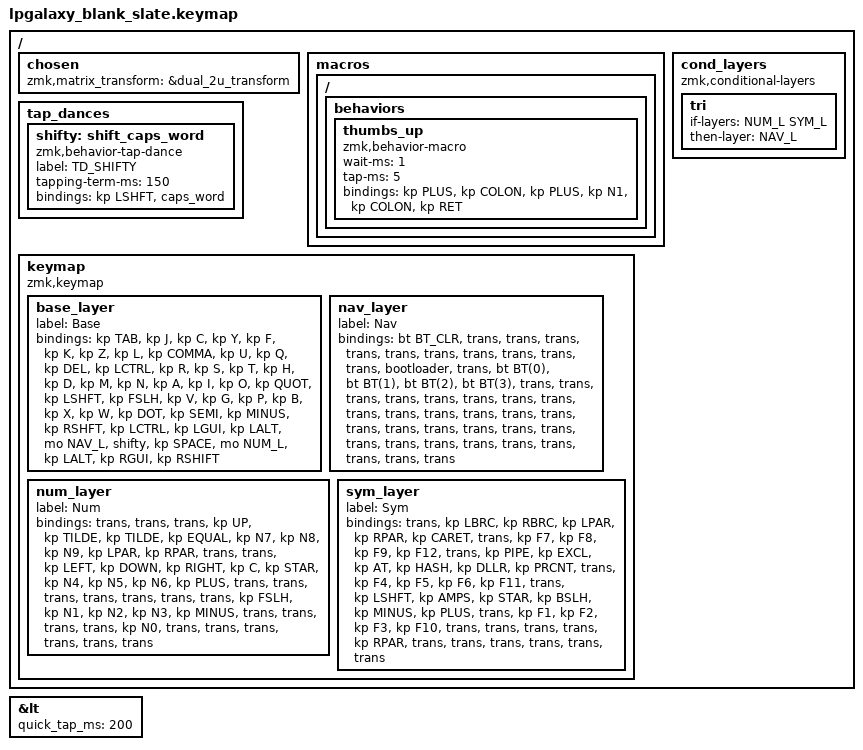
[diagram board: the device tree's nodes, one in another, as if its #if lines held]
/*
 * Copyright (c) 2022 Pete Johanson
 *
 * SPDX-License-Identifier: MIT
 */

#include <behaviors.dtsi>
#include <dt-bindings/zmk/keys.h>
#include <dt-bindings/zmk/bt.h>
#include <dt-bindings/zmk/outputs.h>

#define QWERTY_BASE 1

#define TBLE_ORTHO   1
// #define TBLE_MIT     1
// #define TBLE_DUAL_2U 1

#define NAV_L 1
#define NUM_L 2
#define SYM_L 3

// Using layer taps on thumbs, having quick tap as well helps w/ repeating space/backspace
&lt { quick_tap_ms = <200>; };

#define BT(n) BT_SEL n

/ {
    chosen {
       zmk,matrix_transform =
#ifdef TBLE_DUAL_2U
                       &dual_2u_transform;
#elif defined(TBLE_MIT)
                       &mit_transform;
#else
                       &ortho_transform;
#endif
    };

    macros {
      ZMK_MACRO(thumbs_up,
		wait-ms = <1>;
		tap-ms = <5>;
                bindings = <&kp PLUS &kp COLON &kp PLUS &kp N1 &kp COLON &kp RET>;
		)
    };
    
    tap_dances {
    	shifty: shift_caps_word {
		compatible = "zmk,behavior-tap-dance";
		label = "TD_SHIFTY";
		#binding-cells = <0>;
		tapping-term-ms = <150>;
		bindings = <&kp LSHFT>, <&caps_word>;
	};
    };

// Conditional layer only when we have less thumb keys
#ifdef TBLE_DUAL_2U
    cond_layers {
        compatible = "zmk,conditional-layers";
	tri {
	    if-layers = <NUM_L SYM_L>;
	    then-layer = <NAV_L>;
        };
    };
#endif

    keymap {
        compatible = "zmk,keymap";

        base_layer {
            label = "Base";
            bindings = <
#ifdef QWERTY_BASE
 &kp TAB    &kp J      &kp C      &kp Y       &kp F          &kp K          &kp Z            &kp L          &kp COMMA   &kp U      &kp Q         &kp DEL
 &kp LCTRL  &kp R      &kp S      &kp T       &kp H          &kp D          &kp M            &kp N          &kp A       &kp I      &kp O         &kp QUOT
 &kp LSHFT  &kp FSLH   &kp V      &kp G       &kp P          &kp B          &kp X            &kp W          &kp DOT     &kp SEMI   &kp MINUS     &kp RSHFT
#else
 &kp ESC    &kp Q      &kp W      &kp F       &kp P          &kp B          &kp J            &kp L          &kp U       &kp Y      &kp QUOT      &kp BKSP
 &kp TAB    &kp A      &kp R      &kp S       &kp T          &kp G          &kp M            &kp N          &kp E       &kp I      &kp O         &kp QUOT
 &kp LSHFT  &kp Z      &kp X      &kp C       &kp D          &kp V          &kp K            &kp H          &kp COMMA   &kp DOT    &kp SEMI      &kp RET
#endif
#ifdef TBLE_DUAL_2U
 &kp LCTRL  &kp LGUI   &kp LALT   &mo NAV_L         &shifty                        &kp SPACE                &mo NUM_L   &kp LALT   &kp RGUI      &kp RSHIFT
#elif defined(TBLE_MIT)
 &kp LCTRL  &mo SYM_L  &kp LGUI   &kp LALT    &mo NAV_L          &kp SPACE                   &mo NUM_L      &kp LEFT    &kp UP     &kp DOWN      &kp RIGHT
#else
 &kp A      &kp A      &kp A      &kp LALT    &lt NUM_L E    &kp BKSP       &kp RET          &lt SYM_L SPACE &kp ESC    &kp A      &kp A         &mo NAV_L
#endif
            >;
        };

        nav_layer {
            label = "Nav";
            bindings = <
&bt BT_CLR  &trans     &trans     &trans      &trans         &trans         &trans           &trans         &trans      &trans     &trans       &bootloader
&trans      &bt BT(0)  &bt BT(1)  &bt BT(2)   &bt BT(3)      &trans         &trans           &trans         &trans      &trans     &trans       &trans
&trans      &trans     &trans     &trans      &trans         &trans         &trans           &trans         &trans      &trans     &trans       &trans
#ifdef TBLE_DUAL_2U
&trans      &trans     &trans     &trans              &trans                    &trans                      &trans      &trans     &trans       &trans
#elif defined(TBLE_MIT)
&trans      &trans     &trans     &trans      &trans                &trans                   &trans         &trans      &trans     &trans       &trans
#else
&trans      &trans     &trans     &trans      &trans         &trans         &trans           &trans         &trans      &trans     &trans       &trans
#endif
            >;
        };

        num_layer {
            label = "Num";
            bindings = <
&trans      &trans     &trans     &kp UP      &kp TILDE      &kp TILDE      &kp EQUAL        &kp N7         &kp N8      &kp N9    &kp LPAR    &kp RPAR
&trans      &trans     &kp LEFT   &kp DOWN    &kp RIGHT      &kp C          &kp STAR         &kp N4         &kp N5      &kp N6    &kp PLUS      &trans
&trans      &trans     &trans     &trans      &trans         &trans         &kp FSLH         &kp N1         &kp N2      &kp N3    &kp MINUS      &trans
#ifdef TBLE_DUAL_2U
&trans     &trans     &trans      &kp N0              &trans                 &trans                         &trans      &trans     &trans       &trans
#elif defined(TBLE_MIT)
&trans     &trans     &trans      &kp N0      &trans           &none            &trans                      &kp DEL     &trans     &trans       &trans
#else
&trans     &trans     &trans      &trans      &trans         &kp BKSP       &kp COMMA         &kp N0        &kp DOT     &trans     &trans       &trans
#endif
            >;
        };

        sym_layer {
            label = "Sym";
            bindings = <
&trans     &kp LBRC   &kp RBRC    &kp LPAR    &kp RPAR       &kp CARET      &trans            &kp F7        &kp F8      &kp F9     &kp F12     &trans
&kp PIPE   &kp EXCL   &kp AT      &kp HASH    &kp DLLR       &kp PRCNT      &trans            &kp F4        &kp F5      &kp F6     &kp F11     &trans
&kp LSHFT  &kp AMPS   &kp STAR    &kp BSLH    &kp MINUS      &kp PLUS       &trans            &kp F1        &kp F2      &kp F3     &kp F10     &trans
#ifdef TBLE_DUAL_2U
&trans &trans        &trans     &kp RPAR                &trans                    &trans       &trans         &trans &trans &trans
#elif defined(TBLE_MIT)
&trans &trans        &trans     &kp RPAR        &trans                &trans             &trans      &trans   &trans &trans &trans
#else
&trans     &trans     &trans      &trans      &trans         &kp BKSP       &trans            &trans        &trans      &trans     &trans      &trans
#endif
            >;
        };


    };
};
